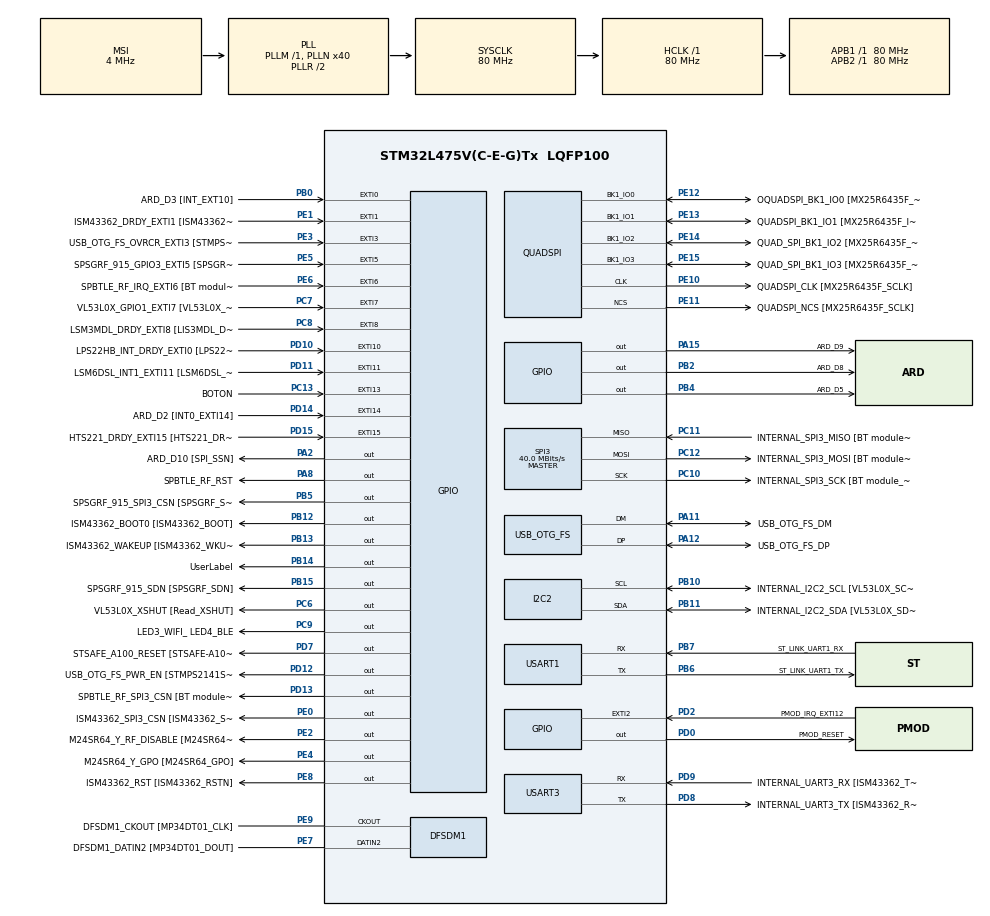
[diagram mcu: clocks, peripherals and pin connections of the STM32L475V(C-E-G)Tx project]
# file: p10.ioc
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FREERTOS.Queues01=qMqttTx,8,1060,1,Dynamic,NULL,NULL;qCmdRx,5,uint8_t,0,Dynamic,NULL,NULL
FREERTOS.Tasks01=WifiTask,24,512,StartWifiTask,Default,NULL,Dynamic,NULL,NULL;MQTT_Task,8,1280,MQTT_TaskFun,Default,NULL,Dynamic,NULL,NULL;task_envRead,24,512,task_envReadFunc,Default,NULL,Dynamic,NULL,NULL;Accel_Task,24,1024,Accel_Task_Func,Default,NULL,Dynamic,NULL,NULL;UartCfgTask,8,512,UartCfgTask_Func,Default,NULL,Dynamic,NULL,NULL
FREERTOS.configTOTAL_HEAP_SIZE=28000
FREERTOS.configUSE_NEWLIB_REENTRANT=1
I2C2.Timing=0x10D19CE4
Mcu.Family=STM32L4
Mcu.Name=STM32L475V(C-E-G)Tx
Mcu.Package=LQFP100
NVIC.EXTI15_10_IRQn=true\:5\:0\:false\:false\:true\:true\:true\:true\:true
NVIC.EXTI1_IRQn=true\:5\:0\:true\:false\:true\:false\:true\:true\:true
NVIC.EXTI9_5_IRQn=true\:5\:0\:false\:false\:true\:true\:true\:true\:true
NVIC.PriorityGroup=NVIC_PRIORITYGROUP_4
NVIC.RTC_Alarm_IRQn=true\:5\:0\:false\:false\:true\:true\:true\:true\:true
NVIC.SPI3_IRQn=true\:5\:0\:true\:false\:false\:false\:true\:true\:true
NVIC.TIM6_DAC_IRQn=true\:15\:0\:false\:false\:true\:false\:false\:true\:true
NVIC.TimeBase=TIM6_DAC_IRQn
NVIC.TimeBaseIP=TIM6
NVIC.USART3_IRQn=true\:5\:0\:false\:false\:true\:true\:true\:true\:true
PA0.GPIO_Label=ARD_D1 [UART4_TX]
PA0.Signal=UART4_TX
PA1.GPIO_Label=ARD_D0 [UART4_RX]
PA1.Signal=UART4_RX
PA10.GPIO_Label=USB_OTG_FS_ID
PA10.Signal=USB_OTG_FS_ID
PA11.GPIO_Label=USB_OTG_FS_DM
PA11.Mode=Device_Only
PA11.Signal=USB_OTG_FS_DM
PA12.GPIO_Label=USB_OTG_FS_DP
PA12.Mode=Device_Only
PA12.Signal=USB_OTG_FS_DP
PA13\ (JTMS-SWDIO).GPIO_Label=SYS_JTMS_SWDIO
PA13\ (JTMS-SWDIO).Mode=Trace_Asynchronous_SW
PA13\ (JTMS-SWDIO).Signal=SYS_JTMS-SWDIO
PA14\ (JTCK-SWCLK).GPIO_Label=SYS_JTCK_SWCLK
PA14\ (JTCK-SWCLK).Mode=Trace_Asynchronous_SW
PA14\ (JTCK-SWCLK).Signal=SYS_JTCK-SWCLK
PA15\ (JTDI).GPIO_Label=ARD_D9
PA15\ (JTDI).Signal=GPIO_Output
PA2.GPIO_Label=ARD_D10 [SPI_SSN]
PA2.Signal=GPIO_Output
PA3.GPIO_Label=ARD_D4
PA3.Signal=S_TIM2_CH4
PA4.GPIO_Label=ARD_D7
PA4.Signal=ADCx_IN9
PA5.GPIO_Label=ARD_D13 [SPI1_SCK]
PA5.Signal=SPI1_SCK
PA6.GPIO_Label=ARD_D12 [SPI1_MISO]
PA6.Signal=SPI1_MISO
PA7.GPIO_Label=ARD_D11 [SPI1_MOSI]
PA7.Signal=SPI1_MOSI
PA8.GPIO_Label=SPBTLE_RF_RST
PA8.Signal=GPIO_Output
PA9.GPIO_Label=USB_OTG_FS_VBUS [STMPS2141STR_OUT]
PA9.Signal=USB_OTG_FS_VBUS
PB0.GPIO_Label=ARD_D3 [INT_EXT10]
PB0.Signal=GPXTI0
PB1.GPIO_Label=ARD_D6 [ADC1_IN6]
PB1.Signal=ADCx_IN16
PB10.GPIO_Label=INTERNAL_I2C2_SCL [VL53L0X_SCL]
PB10.GPIO_Pu=GPIO_PULLUP
PB10.Mode=I2C
PB10.Signal=I2C2_SCL
PB11.GPIO_Label=INTERNAL_I2C2_SDA [VL53L0X_SDA]
PB11.GPIO_Pu=GPIO_PULLUP
PB11.Mode=I2C
PB11.Signal=I2C2_SDA
PB12.GPIO_Label=ISM43362_BOOT0 [ISM43362_BOOT]
PB12.Signal=GPIO_Output
PB13.GPIO_Label=ISM43362_WAKEUP [ISM43362_WKUP]
PB13.Signal=GPIO_Output
PB14.GPIO_Label=UserLabel
PB14.Signal=GPIO_Output
PB15.GPIO_Label=SPSGRF_915_SDN [SPSGRF_SDN]
PB15.Signal=GPIO_Output
PB2.GPIO_Label=ARD_D8
PB2.Signal=GPIO_Output
PB3\ (JTDO-TRACESWO).GPIO_Label=SYS_JTD0_SWO
PB3\ (JTDO-TRACESWO).Mode=Trace_Asynchronous_SW
PB3\ (JTDO-TRACESWO).Signal=SYS_JTDO-SWO
PB4\ (NJTRST).GPIO_Label=ARD_D5
PB4\ (NJTRST).Signal=GPIO_Output
PB5.GPIO_Label=SPSGRF_915_SPI3_CSN [SPSGRF_SPI_CS]
PB5.PinState=GPIO_PIN_SET
PB5.Signal=GPIO_Output
PB6.GPIO_Label=ST_LINK_UART1_TX
PB6.Mode=Asynchronous
PB6.Signal=USART1_TX
PB7.GPIO_Label=ST_LINK_UART1_RX
PB7.Mode=Asynchronous
PB7.Signal=USART1_RX
PB8.GPIO_Label=ARD_D15 [I2C1_SCL]
PB8.Signal=I2C1_SCL
PB9.GPIO_Label=ARD_D14 [I2C1_SDA]
PB9.Signal=I2C1_SDA
PC0.GPIO_Label=ARD_A5 [ADC]
PC0.Signal=ADCx_IN1
PC1.GPIO_Label=ARD_A4 [ADC]
PC1.Signal=ADCx_IN2
PC10.GPIO_Label=INTERNAL_SPI3_SCK [BT module_SPI_SCLK] [ISM43362_SCK]
PC10.Mode=Full_Duplex_Master
PC10.Signal=SPI3_SCK
PC11.GPIO_Label=INTERNAL_SPI3_MISO [BT module_SPI_MISO] [ISM43362_MISO]
PC11.Mode=Full_Duplex_Master
PC11.Signal=SPI3_MISO
PC12.GPIO_Label=INTERNAL_SPI3_MOSI [BT module_SPI_MOSI] [ISM43362_MOSI]
PC12.Mode=Full_Duplex_Master
PC12.Signal=SPI3_MOSI
PC13.GPIO_Label=BOTON
PC13.GPIO_ModeDefaultEXTI=GPIO_MODE_IT_FALLING
PC13.Signal=GPXTI13
PC14-OSC32_IN\ (PC14).Mode=LSE-External-Oscillator
PC14-OSC32_IN\ (PC14).Signal=RCC_OSC32_IN
PC15-OSC32_OUT\ (PC15).Mode=LSE-External-Oscillator
PC15-OSC32_OUT\ (PC15).Signal=RCC_OSC32_OUT
PC2.GPIO_Label=ARD_A3 [ADC]
PC2.Signal=ADCx_IN3
PC3.GPIO_Label=ARD_A2 [ADC]
PC3.Signal=ADCx_IN4
PC4.GPIO_Label=ARD_A1 [ADC]
PC4.Signal=ADCx_IN13
PC5.GPIO_Label=ARD_A0 [ADC]
PC5.Signal=ADCx_IN14
PC6.GPIO_Label=VL53L0X_XSHUT [Read_XSHUT]
PC6.Signal=GPIO_Output
PC7.GPIO_Label=VL53L0X_GPIO1_EXTI7 [VL53L0X_GPIO1]
PC7.Signal=GPXTI7
PC8.GPIO_Label=LSM3MDL_DRDY_EXTI8 [LIS3MDL_DRDY]
PC8.Signal=GPXTI8
PC9.GPIO_Label=LED3_WIFI_ LED4_BLE
PC9.Signal=GPIO_Output
PD0.GPIO_Label=PMOD_RESET
PD0.Signal=GPIO_Output
PD1.GPIO_Label=PMOD_SPI2_SCK
PD1.Signal=SPI2_SCK
PD10.GPIO_Label=LPS22HB_INT_DRDY_EXTI0 [LPS22HB_INT_DRDY] 
PD10.Signal=GPXTI10
PD11.GPIO_Label=LSM6DSL_INT1_EXTI11 [LSM6DSL_INT1]
PD11.Signal=GPXTI11
PD12.GPIO_Label=USB_OTG_FS_PWR_EN [STMPS2141STR_EN]
PD12.Signal=GPIO_Output
PD13.GPIO_Label=SPBTLE_RF_SPI3_CSN [BT module_SPI_CS]
PD13.PinState=GPIO_PIN_SET
PD13.Signal=GPIO_Output
PD14.GPIO_Label=ARD_D2 [INT0_EXTI14]
PD14.Signal=GPXTI14
PD15.GPIO_Label=HTS221_DRDY_EXTI15 [HTS221_DRDY]
PD15.Signal=GPXTI15
PD2.GPIO_Label=PMOD_IRQ_EXTI12
PD2.Signal=GPXTI2
PD3.GPIO_Label=PMOD_UART2_CTS
PD3.Signal=USART2_CTS
PD4.GPIO_Label=PMOD_UART2_RTS
PD4.Signal=USART2_RTS
PD5.GPIO_Label=PMOD_UART2_TX
PD5.Signal=USART2_TX
PD6.GPIO_Label=PMOD_UART2_RX
PD6.Signal=USART2_RX
PD7.GPIO_Label=STSAFE_A100_RESET [STSAFE-A100_RESET]
PD7.Signal=GPIO_Output
PD8.GPIO_Label=INTERNAL_UART3_TX [ISM43362_RX]
PD8.Mode=Asynchronous
PD8.Signal=USART3_TX
PD9.GPIO_Label=INTERNAL_UART3_RX [ISM43362_TX]
PD9.Mode=Asynchronous
PD9.Signal=USART3_RX
PE0.GPIO_Label=ISM43362_SPI3_CSN [ISM43362_SSN]
PE0.PinState=GPIO_PIN_SET
PE0.Signal=GPIO_Output
PE1.GPIO_Label=ISM43362_DRDY_EXTI1 [ISM43362_DATARDY]
PE1.Signal=GPXTI1
PE10.GPIO_Label=QUADSPI_CLK [MX25R6435F_SCLK]
PE10.Mode=Single Bank
PE10.Signal=QUADSPI_CLK
PE11.GPIO_Label=QUADSPI_NCS [MX25R6435F_SCLK]
PE11.Mode=Single Bank
PE11.Signal=QUADSPI_NCS
PE12.GPIO_Label=OQUADSPI_BK1_IO0 [MX25R6435F_IO0]
PE12.Mode=Single Bank
PE12.Signal=QUADSPI_BK1_IO0
PE13.GPIO_Label=QUADSPI_BK1_IO1 [MX25R6435F_IO1]
PE13.Mode=Single Bank
PE13.Signal=QUADSPI_BK1_IO1
PE14.GPIO_Label=QUAD_SPI_BK1_IO2 [MX25R6435F_IO2]
PE14.Mode=Single Bank
PE14.Signal=QUADSPI_BK1_IO2
PE15.GPIO_Label=QUAD_SPI_BK1_IO3 [MX25R6435F_IO3]
PE15.Mode=Single Bank
PE15.Signal=QUADSPI_BK1_IO3
PE2.GPIO_Label=M24SR64_Y_RF_DISABLE [M24SR64_RFDIS]
PE2.Signal=GPIO_Output
PE3.GPIO_Label=USB_OTG_FS_OVRCR_EXTI3 [STMPS2141STR_FAULT]
PE3.Signal=GPXTI3
PE4.GPIO_Label=M24SR64_Y_GPO [M24SR64_GPO]
PE4.Signal=GPIO_Output
PE5.GPIO_Label=SPSGRF_915_GPIO3_EXTI5 [SPSGRF_GPIO_3]
PE5.Signal=GPXTI5
PE6.GPIO_Label=SPBTLE_RF_IRQ_EXTI6 [BT module_SPI_IRQ]
PE6.Signal=GPXTI6
PE7.GPIO_Label=DFSDM1_DATIN2 [MP34DT01_DOUT]
PE7.Signal=S_DATAIN2DFSDM1
PE8.GPIO_Label=ISM43362_RST [ISM43362_RSTN]
PE8.Signal=GPIO_Output
PE9.GPIO_Label=DFSDM1_CKOUT [MP34DT01_CLK]
PE9.Signal=S_CKOUTDFSDM1
ProjectManager.HeapSize=0x200
ProjectManager.StackSize=0x400
ProjectManager.TargetToolchain=STM32CubeIDE
QUADSPI.ClockPrescaler=2
QUADSPI.FifoThreshold=4
QUADSPI.FlashSize=23
QUADSPI.SampleShifting=QSPI_SAMPLE_SHIFTING_HALFCYCLE
RCC.ADCFreq_Value=48000000
RCC.AHBFreq_Value=80000000
RCC.APB1Freq_Value=80000000
RCC.APB1TimFreq_Value=80000000
RCC.APB2Freq_Value=80000000
RCC.APB2TimFreq_Value=80000000
RCC.CortexFreq_Value=80000000
RCC.HCLKFreq_Value=80000000
RCC.HSE_VALUE=8000000
RCC.HSI_VALUE=16000000
RCC.MSI_VALUE=4000000
RCC.PLLN=40
RCC.PLLSAI1N=24
RCC.SYSCLKFreq_VALUE=80000000
RCC.SYSCLKSource=RCC_SYSCLKSOURCE_PLLCLK
RCC.USBFreq_Value=48000000
RCC.VCOOutputFreq_Value=160000000
RTC.Alarm-Alarm\ A=RTC_ALARM_A
SH.ADCx_IN1.0=ADC1_IN1
SH.ADCx_IN13.0=ADC1_IN13
SH.ADCx_IN14.0=ADC1_IN14
SH.ADCx_IN16.0=ADC1_IN16
SH.ADCx_IN2.0=ADC1_IN2
SH.ADCx_IN3.0=ADC1_IN3
SH.ADCx_IN4.0=ADC1_IN4
SH.ADCx_IN9.0=ADC1_IN9
SH.S_CKOUTDFSDM1.0=DFSDM1_CKOUT,CKOUT
SH.S_CKOUTDFSDM1.1=DFSDM1_CKOUT,PDM_SPI_Input_from_ch12_and_Internal_Clock
SH.S_DATAIN2DFSDM1.0=DFSDM1_DATIN2,PDM_SPI_Input_from_ch12_and_Internal_Clock
SH.S_TIM2_CH4.0=TIM2_CH4
SPI3.CalculateBaudRate=40.0 MBits/s
SPI3.Direction=SPI_DIRECTION_2LINES
SPI3.Mode=SPI_MODE_MASTER
SPI3.VirtualType=VM_MASTER
USART1.VirtualMode-Asynchronous=VM_ASYNC
USART3.VirtualMode-Asynchronous=VM_ASYNC
USB_OTG_FS.VirtualMode=Device_Only
VP_FREERTOS_VS_CMSIS_V2.Mode=CMSIS_V2
VP_RTC_VS_RTC_Activate.Mode=RTC_Enabled
VP_RTC_VS_RTC_Alarm_A_Intern.Mode=Alarm A
VP_RTC_VS_RTC_Calendar.Mode=RTC_Calendar
VP_SYS_VS_tim6.Mode=TIM6
board=B-L475E-IOT01A1

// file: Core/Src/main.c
/* USER CODE BEGIN Header */
/**
  ******************************************************************************
  * @file           : main.c
  * @brief          : Main program body
  ******************************************************************************
  * @attention
  *
  * Copyright (c) 2026 STMicroelectronics.
  * All rights reserved.
  *
  * This software is licensed under terms that can be found in the LICENSE file
  * in the root directory of this software component.
  * If no LICENSE file comes with this software, it is provided AS-IS.
  *
  ******************************************************************************
  */
/* USER CODE END Header */
#include "main.h"
#include "cmsis_os.h"

/* USER CODE BEGIN Includes */
#include "common_def.h"
#include "cmd_parser.h"
#include "es_wifi.h"
#include "wifi.h"
#include "stm32l4xx_hal_uart.h"
#include "stdio.h"
#include "mqtt_priv.h"
#include "mqtt_priv_config.h"
//#include "transport_interface.h"
#include "stm32l475e_iot01.h"
#include "stm32l475e_iot01_tsensor.h"
#include "stm32l475e_iot01_hsensor.h"
#include "lsm6dsl.h"
#include"stm32l475e_iot01_accelero.h"
#include <string.h>
#include <stdarg.h>

/* USER CODE END Includes */

/* USER CODE BEGIN PD */
#define FLAG_DATA_READY 0x00000001U
/* ===== DEBUG MENU ===== */
#ifdef DEBUG
  #define DEBUG_MENU 1
#else
  #define DEBUG_MENU 0
#endif

/*
 * Vasriable para el tipo de nodo
 * 1 == ACELEROMETRO
 * 2 == ENVIRONMENT
 * */
#define NODE_ID 1

//#define PROJECT_TYPE 0
/* USER CODE END PD */

DFSDM_Channel_HandleTypeDef hdfsdm1_channel1;

I2C_HandleTypeDef hi2c2;

QSPI_HandleTypeDef hqspi;

RTC_HandleTypeDef hrtc;

SPI_HandleTypeDef hspi3;

UART_HandleTypeDef huart1;
UART_HandleTypeDef huart3;

PCD_HandleTypeDef hpcd_USB_OTG_FS;

/* Definitions for WifiTask */
osThreadId_t WifiTaskHandle;
const osThreadAttr_t WifiTask_attributes = {
  .name = "WifiTask",
  .stack_size = 512 * 4,
  .priority = (osPriority_t) osPriorityNormal,
};
/* Definitions for MQTT_Task */
osThreadId_t MQTT_TaskHandle;
const osThreadAttr_t MQTT_Task_attributes = {
  .name = "MQTT_Task",
  .stack_size = 1024 * 4,
  .priority = (osPriority_t) osPriorityLow,
};
/* Definitions for task_envRead */
osThreadId_t task_envReadHandle;
const osThreadAttr_t task_envRead_attributes = {
  .name = "task_envRead",
  .stack_size = 512 * 4,
  .priority = (osPriority_t) osPriorityNormal,
};
/* Definitions for Accel_Task */
osThreadId_t Accel_TaskHandle;
const osThreadAttr_t Accel_Task_attributes = {
  .name = "Accel_Task",
  .stack_size = 1024 * 4,
  .priority = (osPriority_t) osPriorityNormal,
};
/* Definitions for UartCfgTask */
osThreadId_t UartCfgTaskHandle;
const osThreadAttr_t UartCfgTask_attributes = {
  .name = "UartCfgTask",
  .stack_size = 512 * 4,
  .priority = (osPriority_t) osPriorityLow,
};
/* Definitions for qMqttTx */
osMessageQueueId_t qMqttTxHandle;
const osMessageQueueAttr_t qMqttTx_attributes = {
  .name = "qMqttTx"
};
/* Definitions for qCmdRx */
osMessageQueueId_t qCmdRxHandle;
const osMessageQueueAttr_t qCmdRx_attributes = {
  .name = "qCmdRx"
};
/* USER CODE BEGIN PV */

char g_wifi_ssid[WIFI_SSID_MAX] = "manolo";
char g_wifi_pass[WIFI_PASS_MAX] = "123456789";
#define WIFISECURITY WIFI_ECN_WPA2_PSK

volatile uint16_t g_acc_odr_hz = 52;
volatile uint8_t  g_acc_fs_g   = 2;

extern UART_HandleTypeDef huart1;
static osMutexId_t uartTxMutexHandle;
static const osMutexAttr_t uartTxMutex_attributes = { .name = "uartTxMutex" };

static uint8_t  uart_rx_ch;
static char     uart_line[UART_LINE_MAX];
static volatile uint16_t uart_line_len = 0;
static char uart_line_ready[UART_LINE_MAX];
static volatile uint8_t uart_line_has_ready = 0;

// Variables globales de estado
volatile uint8_t WIFI_IS_CONNECTED = 0;
volatile uint8_t NET_MQTT_OK = 0;

volatile uint8_t WIFI_STATE = 0;
// 0=DISCONNECTED, 1=CONNECTING, 2=CONNECTED

#define PORT 	80
#define WIFI_WRITE_TIMEOUT 10000
#define WIFI_READ_TIMEOUT 10000

uint8_t Alert_Flag = 0;

/*#define TERMINAL_USE
#ifdef  TERMINAL_USE
#else
#define LOG(a)
#endif*/
/* USER CODE END PV */

void SystemClock_Config(void);
static void MX_GPIO_Init(void);
static void MX_DFSDM1_Init(void);
static void MX_I2C2_Init(void);
static void MX_QUADSPI_Init(void);
static void MX_SPI3_Init(void);
static void MX_USART1_UART_Init(void);
static void MX_USART3_UART_Init(void);
static void MX_USB_OTG_FS_PCD_Init(void);
static void MX_RTC_Init(void);
void StartWifiTask(void *argument);
void MQTT_TaskFun(void *argument);
void task_envReadFunc(void *argument);
void Accel_Task_Func(void *argument);
void UartCfgTask_Func(void *argument);
static void ApplyRTC(const typeof(((SystemCommandMsg_t*)0)->u.rtc) *rtc);
static void send_mqtt_msg(const char *topic, const char *payload);

/* USER CODE BEGIN PFP */
extern  SPI_HandleTypeDef hspi;
static  uint8_t  IP_Addr[4];
#if defined (TERMINAL_USE)
extern UART_HandleTypeDef hDiscoUart;
#endif /* TERMINAL_USE */

extern ES_WIFIObject_t    EsWifiObj;

/* USER CODE END PFP */

/* USER CODE BEGIN 0 */

static osMutexId_t printMutexHandle;
static const osMutexAttr_t printMutex_attributes = { .name = "printMutex" };

static void dbg_printf(const char *fmt, ...)
{
  if (__get_IPSR() != 0) return;

  if (printMutexHandle) osMutexAcquire(printMutexHandle, osWaitForever);

  va_list ap;
  va_start(ap, fmt);
  vprintf(fmt, ap);
  va_end(ap);

  if (printMutexHandle) osMutexRelease(printMutexHandle);
}

static void log_printf(const char *fmt, ...)
{
  char line[256];
  va_list ap;
  va_start(ap, fmt);
  vsnprintf(line, sizeof(line), fmt, ap);
  va_end(ap);

  dbg_printf("%s", line);

  if (!NET_MQTT_OK || !WIFI_IS_CONNECTED) return;
  if (strstr(line, "bridge/log/") != NULL) return;
  if (strstr(line, "[MQTT] Enviando Topic: bridge/log/") != NULL) return;

  char topic[MSG_TOPIC_SIZE];
  snprintf(topic, sizeof(topic), "bridge/log/%d", NODE_ID);
  send_mqtt_msg(topic, line);
}

static void PrintDebugMenu(void)
{
#if DEBUG_MENU
  dbg_printf("\r\n");
  dbg_printf("========================================\r\n");
  dbg_printf("   MENU DEBUG - COMANDOS DISPONIBLES\r\n");
  dbg_printf("========================================\r\n");
  dbg_printf("UART (terminal) y MQTT (bridge/cmd/<id>)\r\n");
  dbg_printf("\r\n");
  dbg_printf("Acelerometro:\r\n");
  dbg_printf("  CONT ON              -> modo continuo\r\n");
  dbg_printf("  CONT OFF             -> modo normal\r\n");
  dbg_printf("  READ                 -> forzar lectura\r\n");
  dbg_printf("\r\n");
  dbg_printf("WiFi:\r\n");
  dbg_printf("  WIFI <ssid> <pass>   -> cambiar credenciales\r\n");
  dbg_printf("     ej: WIFI MiRed 12345678\r\n");
  dbg_printf("\r\n");
  dbg_printf("RTC:\r\n");
  dbg_printf("  RTC 2026-02-08 19:30:00\r\n");
  dbg_printf("  RTC 2026 2 8 19 30 0\r\n");
  dbg_printf("\r\n");
  dbg_printf("MQTT topic de control:\r\n");
  dbg_printf("  bridge/cmd/1  (nodo 1)\r\n");
  dbg_printf("  bridge/cmd/2  (nodo 2)\r\n");
  dbg_printf("========================================\r\n\r\n");
#endif
}

static void DispatchCommand(const SystemCommandMsg_t *cmd);

void OnMqttControlMessage(const char *topic, const char *payload)
{
  (void)topic;
  SystemCommandMsg_t cmd;
  if (!Cmd_ParseLine(payload, CMD_SRC_MQTT, &cmd)) {
    dbg_printf("[MQTT][CTRL] cmd invalido: %s\r\n", payload);
    return;
  }
  DispatchCommand(&cmd);
}

static void DispatchCommand(const SystemCommandMsg_t *cmd)
{
  osMessageQueuePut(qCmdRxHandle, cmd, 0, pdMS_TO_TICKS(50));
  #if NODE_ID == NODE_ID_ACCEL
    osThreadFlagsSet(Accel_TaskHandle, NOTE_CMD_RX);
  #elif NODE_ID == NODE_ID_ENV
    osThreadFlagsSet(task_envReadHandle, NOTE_CMD_RX);
  #endif
}

void program_alarm_RTC(void)
{
  RTC_AlarmTypeDef sAlarm = {0};
  RTC_TimeTypeDef  sTime  = {0};
  RTC_DateTypeDef  sDate  = {0};

  HAL_RTC_GetTime(&hrtc, &sTime, RTC_FORMAT_BIN);
  HAL_RTC_GetDate(&hrtc, &sDate, RTC_FORMAT_BIN);
  HAL_RTC_DeactivateAlarm(&hrtc, RTC_ALARM_A);
  __HAL_RTC_ALARM_CLEAR_FLAG(&hrtc, RTC_FLAG_ALRAF);
  __HAL_RTC_ALARM_EXTI_CLEAR_FLAG();

  uint8_t nextMin = sTime.Minutes + 1;
  uint8_t nextHr  = sTime.Hours;

  if (nextMin >= 60) { nextMin = 0; nextHr = (nextHr + 1) % 24; }

  sAlarm.AlarmTime.Hours   = nextHr;
  sAlarm.AlarmTime.Minutes = nextMin;
  sAlarm.AlarmTime.Seconds = 0;

  sAlarm.AlarmMask = RTC_ALARMMASK_DATEWEEKDAY;
  sAlarm.AlarmSubSecondMask = RTC_ALARMSUBSECONDMASK_ALL;
  sAlarm.AlarmDateWeekDaySel = RTC_ALARMDATEWEEKDAYSEL_DATE;
  sAlarm.AlarmDateWeekDay = 1;
  sAlarm.Alarm = RTC_ALARM_A;

  if (HAL_RTC_SetAlarm_IT(&hrtc, &sAlarm, RTC_FORMAT_BIN) != HAL_OK)
  {
    Error_Handler();
  }
}

static void ApplyRTC(const typeof(((SystemCommandMsg_t*)0)->u.rtc) *rtc)
{
  RTC_TimeTypeDef sTime = {0};
  RTC_DateTypeDef sDate = {0};

  sTime.Hours   = rtc->hour;
  sTime.Minutes = rtc->min;
  sTime.Seconds = rtc->sec;
  sTime.DayLightSaving = RTC_DAYLIGHTSAVING_NONE;
  sTime.StoreOperation = RTC_STOREOPERATION_RESET;

  uint16_t y = rtc->year;
  if (y >= 2000) y -= 2000;

  sDate.Year  = (uint8_t)y;
  sDate.Month = rtc->month;
  sDate.Date  = rtc->day;
  sDate.WeekDay = RTC_WEEKDAY_MONDAY;

  HAL_RTC_DeactivateAlarm(&hrtc, RTC_ALARM_A);

  if (HAL_RTC_SetTime(&hrtc, &sTime, RTC_FORMAT_BIN) != HAL_OK) {
	dbg_printf("[RTC] Error SetTime\r\n");
    return;
  }
  if (HAL_RTC_SetDate(&hrtc, &sDate, RTC_FORMAT_BIN) != HAL_OK) {
	dbg_printf("[RTC] Error SetDate\r\n");
    return;
  }

  dbg_printf("[RTC] Ajustado: %04u-%02u-%02u %02u:%02u:%02u\r\n",
         (unsigned)rtc->year, rtc->month, rtc->day,
         rtc->hour, rtc->min, rtc->sec);
}

static int wifi_start(void)
{
	uint8_t  MAC_Addr[6];
 /*Initialize and use WIFI module */
  if(WIFI_Init() ==  WIFI_STATUS_OK)
  {
    log_printf("ES-WIFI Initialized.\r\n");
    if(WIFI_GetMAC_Address(MAC_Addr) == WIFI_STATUS_OK)
    {
    	dbg_printf("> eS-WiFi module MAC Address : %02X:%02X:%02X:%02X:%02X:%02X\r\n",
               MAC_Addr[0],
               MAC_Addr[1],
               MAC_Addr[2],
               MAC_Addr[3],
               MAC_Addr[4],
               MAC_Addr[5]);
    }
    else
    {
    	log_printf("> ERROR : CANNOT get MAC address\r\n");
      return -1;
    }
  }
  else
  {
    return -1;
  }
  return 0;
}

int wifi_connect(void)
{

  wifi_start();

  log_printf("\nConnecting to %s, %s\r\n", g_wifi_ssid, g_wifi_pass);
  if( WIFI_Connect(g_wifi_ssid, g_wifi_pass, WIFISECURITY) == WIFI_STATUS_OK)
  {
    if(WIFI_GetIP_Address(IP_Addr) == WIFI_STATUS_OK)
    {
    	dbg_printf("> es-wifi module connected: got IP Address : %d.%d.%d.%d\r\n",
               IP_Addr[0],
               IP_Addr[1],
               IP_Addr[2],
               IP_Addr[3]);
    }
    else
    {
    	log_printf(" ERROR : es-wifi module CANNOT get IP address\r\n");
      return -1;
    }
  }
  else
  {
	  dbg_printf("ERROR : es-wifi module NOT connected\r\n");
     return -1;
  }
  return 0;
}

void USART1_IRQHandler(void)
{
  HAL_UART_IRQHandler(&huart1);
}
/* USER CODE END 0 */

int main(void)
{

  /* MCU Configuration--------------------------------------------------------*/

  /* Reset of all peripherals, Initializes the Flash interface and the Systick. */
  HAL_Init();

  /* Configure the system clock */
  SystemClock_Config();

  /* Initialize all configured peripherals */
  MX_GPIO_Init();
  MX_DFSDM1_Init();
  MX_I2C2_Init();
  MX_QUADSPI_Init();
  MX_SPI3_Init();
  MX_USART1_UART_Init();
  MX_USART3_UART_Init();
  MX_USB_OTG_FS_PCD_Init();
  MX_RTC_Init();

  /* USER CODE BEGIN 2 */

	log_printf("[BOOT] Forzando Reinicio Fisico del WiFi ---\r\n");

	HAL_GPIO_WritePin(GPIOE, GPIO_PIN_8, GPIO_PIN_RESET);
	HAL_Delay(500);
	HAL_GPIO_WritePin(GPIOE, GPIO_PIN_8, GPIO_PIN_SET);
	HAL_Delay(1000);

	log_printf("[BOOT] WiFi Reiniciado. Iniciando Kernel... ---\r\n");
    HAL_UART_Receive_IT(&huart1, &uart_rx_ch, 1);
    log_printf("[UART] RX listo\r\n");

	PrintDebugMenu();

  /* USER CODE END 2 */

  /* Init scheduler */
  osKernelInitialize();

  /* USER CODE BEGIN RTOS_MUTEX */
  /* add mutexes, ... */
  uartTxMutexHandle = osMutexNew(&uartTxMutex_attributes);
  printMutexHandle = osMutexNew(&printMutex_attributes);

  /* USER CODE END RTOS_MUTEX */

  /* Create the queue(s) */
  /* creation of qMqttTx */
  qMqttTxHandle = osMessageQueueNew (8, sizeof(MqttMsg_t*), &qMqttTx_attributes);

  /* creation of qCmdRx */
  qCmdRxHandle = osMessageQueueNew (5, sizeof(SystemCommandMsg_t), &qCmdRx_attributes);

  /* Create the thread(s) */
  /* creation of WifiTask */
  WifiTaskHandle = osThreadNew(StartWifiTask, NULL, &WifiTask_attributes);

  /* creation of MQTT_Task */
  MQTT_TaskHandle = osThreadNew(MQTT_TaskFun, NULL, &MQTT_Task_attributes);

#if NODE_ID == 1   // ACC
  Accel_TaskHandle = osThreadNew(Accel_Task_Func, NULL, &Accel_Task_attributes);
#elif NODE_ID == 2 // ENV
  task_envReadHandle = osThreadNew(task_envReadFunc, NULL, &task_envRead_attributes);
#endif

  /* creation of UartCfgTask */
  UartCfgTaskHandle = osThreadNew(UartCfgTask_Func, NULL, &UartCfgTask_attributes);

  /* Start scheduler */
  osKernelStart();

  /* We should never get here as control is now taken by the scheduler */

  /* Infinite loop */
  while (1)
  {

  }
}

void SystemClock_Config(void)
{
  RCC_OscInitTypeDef RCC_OscInitStruct = {0};
  RCC_ClkInitTypeDef RCC_ClkInitStruct = {0};

  /** Configure the main internal regulator output voltage
  */
  if (HAL_PWREx_ControlVoltageScaling(PWR_REGULATOR_VOLTAGE_SCALE1) != HAL_OK)
  {
    Error_Handler();
  }

  /** Configure LSE Drive Capability
  */
  HAL_PWR_EnableBkUpAccess();
  __HAL_RCC_LSEDRIVE_CONFIG(RCC_LSEDRIVE_LOW);

  /** Initializes the RCC Oscillators according to the specified parameters
  * in the RCC_OscInitTypeDef structure.
  */
  RCC_OscInitStruct.OscillatorType = RCC_OSCILLATORTYPE_LSI|RCC_OSCILLATORTYPE_LSE
                              |RCC_OSCILLATORTYPE_MSI;
  RCC_OscInitStruct.LSEState = RCC_LSE_ON;
  RCC_OscInitStruct.LSIState = RCC_LSI_ON;
  RCC_OscInitStruct.MSIState = RCC_MSI_ON;
  RCC_OscInitStruct.MSICalibrationValue = 0;
  RCC_OscInitStruct.MSIClockRange = RCC_MSIRANGE_6;
  RCC_OscInitStruct.PLL.PLLState = RCC_PLL_ON;
  RCC_OscInitStruct.PLL.PLLSource = RCC_PLLSOURCE_MSI;
  RCC_OscInitStruct.PLL.PLLM = 1;
  RCC_OscInitStruct.PLL.PLLN = 40;
  RCC_OscInitStruct.PLL.PLLP = RCC_PLLP_DIV7;
  RCC_OscInitStruct.PLL.PLLQ = RCC_PLLQ_DIV2;
  RCC_OscInitStruct.PLL.PLLR = RCC_PLLR_DIV2;
  if (HAL_RCC_OscConfig(&RCC_OscInitStruct) != HAL_OK)
  {
    Error_Handler();
  }

  /** Initializes the CPU, AHB and APB buses clocks
  */
  RCC_ClkInitStruct.ClockType = RCC_CLOCKTYPE_HCLK|RCC_CLOCKTYPE_SYSCLK
                              |RCC_CLOCKTYPE_PCLK1|RCC_CLOCKTYPE_PCLK2;
  RCC_ClkInitStruct.SYSCLKSource = RCC_SYSCLKSOURCE_PLLCLK;
  RCC_ClkInitStruct.AHBCLKDivider = RCC_SYSCLK_DIV1;
  RCC_ClkInitStruct.APB1CLKDivider = RCC_HCLK_DIV1;
  RCC_ClkInitStruct.APB2CLKDivider = RCC_HCLK_DIV1;

  if (HAL_RCC_ClockConfig(&RCC_ClkInitStruct, FLASH_LATENCY_4) != HAL_OK)
  {
    Error_Handler();
  }

  /** Enable MSI Auto calibration
  */
  HAL_RCCEx_EnableMSIPLLMode();
}

static void MX_DFSDM1_Init(void)
{

  hdfsdm1_channel1.Instance = DFSDM1_Channel1;
  hdfsdm1_channel1.Init.OutputClock.Activation = ENABLE;
  hdfsdm1_channel1.Init.OutputClock.Selection = DFSDM_CHANNEL_OUTPUT_CLOCK_SYSTEM;
  hdfsdm1_channel1.Init.OutputClock.Divider = 2;
  hdfsdm1_channel1.Init.Input.Multiplexer = DFSDM_CHANNEL_EXTERNAL_INPUTS;
  hdfsdm1_channel1.Init.Input.DataPacking = DFSDM_CHANNEL_STANDARD_MODE;
  hdfsdm1_channel1.Init.Input.Pins = DFSDM_CHANNEL_FOLLOWING_CHANNEL_PINS;
  hdfsdm1_channel1.Init.SerialInterface.Type = DFSDM_CHANNEL_SPI_RISING;
  hdfsdm1_channel1.Init.SerialInterface.SpiClock = DFSDM_CHANNEL_SPI_CLOCK_INTERNAL;
  hdfsdm1_channel1.Init.Awd.FilterOrder = DFSDM_CHANNEL_FASTSINC_ORDER;
  hdfsdm1_channel1.Init.Awd.Oversampling = 1;
  hdfsdm1_channel1.Init.Offset = 0;
  hdfsdm1_channel1.Init.RightBitShift = 0x00;
  if (HAL_DFSDM_ChannelInit(&hdfsdm1_channel1) != HAL_OK)
  {
    Error_Handler();
  }

}

static void MX_I2C2_Init(void)
{

  hi2c2.Instance = I2C2;
  hi2c2.Init.Timing = 0x10D19CE4;
  hi2c2.Init.OwnAddress1 = 0;
  hi2c2.Init.AddressingMode = I2C_ADDRESSINGMODE_7BIT;
  hi2c2.Init.DualAddressMode = I2C_DUALADDRESS_DISABLE;
  hi2c2.Init.OwnAddress2 = 0;
  hi2c2.Init.OwnAddress2Masks = I2C_OA2_NOMASK;
  hi2c2.Init.GeneralCallMode = I2C_GENERALCALL_DISABLE;
  hi2c2.Init.NoStretchMode = I2C_NOSTRETCH_DISABLE;
  if (HAL_I2C_Init(&hi2c2) != HAL_OK)
  {
    Error_Handler();
  }

  /** Configure Analogue filter
  */
  if (HAL_I2CEx_ConfigAnalogFilter(&hi2c2, I2C_ANALOGFILTER_ENABLE) != HAL_OK)
  {
    Error_Handler();
  }

  /** Configure Digital filter
  */
  if (HAL_I2CEx_ConfigDigitalFilter(&hi2c2, 0) != HAL_OK)
  {
    Error_Handler();
  }

}

static void MX_QUADSPI_Init(void)
{

  /* QUADSPI parameter configuration*/
  hqspi.Instance = QUADSPI;
  hqspi.Init.ClockPrescaler = 2;
  hqspi.Init.FifoThreshold = 4;
  hqspi.Init.SampleShifting = QSPI_SAMPLE_SHIFTING_HALFCYCLE;
  hqspi.Init.FlashSize = 23;
  hqspi.Init.ChipSelectHighTime = QSPI_CS_HIGH_TIME_1_CYCLE;
  hqspi.Init.ClockMode = QSPI_CLOCK_MODE_0;
  if (HAL_QSPI_Init(&hqspi) != HAL_OK)
  {
    Error_Handler();
  }

}

static void MX_RTC_Init(void)
{

  RTC_TimeTypeDef sTime = {0};
  RTC_DateTypeDef sDate = {0};
  RTC_AlarmTypeDef sAlarm = {0};

  /** Initialize RTC Only
  */
  hrtc.Instance = RTC;
  hrtc.Init.HourFormat = RTC_HOURFORMAT_24;
  hrtc.Init.AsynchPrediv = 127;
  hrtc.Init.SynchPrediv = 255;
  hrtc.Init.OutPut = RTC_OUTPUT_DISABLE;
  hrtc.Init.OutPutRemap = RTC_OUTPUT_REMAP_NONE;
  hrtc.Init.OutPutPolarity = RTC_OUTPUT_POLARITY_HIGH;
  hrtc.Init.OutPutType = RTC_OUTPUT_TYPE_OPENDRAIN;
  if (HAL_RTC_Init(&hrtc) != HAL_OK)
  {
    Error_Handler();
  }

  /** Initialize RTC and set the Time and Date
  */
  sTime.Hours = 0x0;
  sTime.Minutes = 0x0;
  sTime.Seconds = 0x0;
  sTime.DayLightSaving = RTC_DAYLIGHTSAVING_NONE;
  sTime.StoreOperation = RTC_STOREOPERATION_RESET;
  if (HAL_RTC_SetTime(&hrtc, &sTime, RTC_FORMAT_BCD) != HAL_OK)
  {
    Error_Handler();
  }
  sDate.WeekDay = RTC_WEEKDAY_MONDAY;
  sDate.Month = RTC_MONTH_JANUARY;
  sDate.Date = 0x1;
  sDate.Year = 0x0;

  if (HAL_RTC_SetDate(&hrtc, &sDate, RTC_FORMAT_BCD) != HAL_OK)
  {
    Error_Handler();
  }

  /** Enable the Alarm A
  */
  sAlarm.AlarmTime.Hours = 0x0;
  sAlarm.AlarmTime.Minutes = 0x0;
  sAlarm.AlarmTime.Seconds = 0x0;
  sAlarm.AlarmTime.SubSeconds = 0x0;
  sAlarm.AlarmTime.DayLightSaving = RTC_DAYLIGHTSAVING_NONE;
  sAlarm.AlarmTime.StoreOperation = RTC_STOREOPERATION_RESET;
  sAlarm.AlarmMask = RTC_ALARMMASK_NONE;
  sAlarm.AlarmSubSecondMask = RTC_ALARMSUBSECONDMASK_ALL;
  sAlarm.AlarmDateWeekDaySel = RTC_ALARMDATEWEEKDAYSEL_DATE;
  sAlarm.AlarmDateWeekDay = 0x1;
  sAlarm.Alarm = RTC_ALARM_A;
  if (HAL_RTC_SetAlarm_IT(&hrtc, &sAlarm, RTC_FORMAT_BCD) != HAL_OK)
  {
    Error_Handler();
  }

}

static void MX_SPI3_Init(void)
{

  /* SPI3 parameter configuration*/
  hspi3.Instance = SPI3;
  hspi3.Init.Mode = SPI_MODE_MASTER;
  hspi3.Init.Direction = SPI_DIRECTION_2LINES;
  hspi3.Init.DataSize = SPI_DATASIZE_4BIT;
  hspi3.Init.CLKPolarity = SPI_POLARITY_LOW;
  hspi3.Init.CLKPhase = SPI_PHASE_1EDGE;
  hspi3.Init.NSS = SPI_NSS_SOFT;
  hspi3.Init.BaudRatePrescaler = SPI_BAUDRATEPRESCALER_2;
  hspi3.Init.FirstBit = SPI_FIRSTBIT_MSB;
  hspi3.Init.TIMode = SPI_TIMODE_DISABLE;
  hspi3.Init.CRCCalculation = SPI_CRCCALCULATION_DISABLE;
  hspi3.Init.CRCPolynomial = 7;
  hspi3.Init.CRCLength = SPI_CRC_LENGTH_DATASIZE;
  hspi3.Init.NSSPMode = SPI_NSS_PULSE_ENABLE;
  if (HAL_SPI_Init(&hspi3) != HAL_OK)
  {
    Error_Handler();
  }

}

static void MX_USART1_UART_Init(void)
{

  huart1.Instance = USART1;
  huart1.Init.BaudRate = 115200;
  huart1.Init.WordLength = UART_WORDLENGTH_8B;
  huart1.Init.StopBits = UART_STOPBITS_1;
  huart1.Init.Parity = UART_PARITY_NONE;
  huart1.Init.Mode = UART_MODE_TX_RX;
  huart1.Init.HwFlowCtl = UART_HWCONTROL_NONE;
  huart1.Init.OverSampling = UART_OVERSAMPLING_16;
  huart1.Init.OneBitSampling = UART_ONE_BIT_SAMPLE_DISABLE;
  huart1.AdvancedInit.AdvFeatureInit = UART_ADVFEATURE_NO_INIT;
  if (HAL_UART_Init(&huart1) != HAL_OK)
  {
    Error_Handler();
  }
  /* USER CODE BEGIN USART1_Init 2 */

  HAL_NVIC_SetPriority(USART1_IRQn, 5, 0);
  HAL_NVIC_EnableIRQ(USART1_IRQn);

  /* USER CODE END USART1_Init 2 */

}

static void MX_USART3_UART_Init(void)
{

  huart3.Instance = USART3;
  huart3.Init.BaudRate = 115200;
  huart3.Init.WordLength = UART_WORDLENGTH_8B;
  huart3.Init.StopBits = UART_STOPBITS_1;
  huart3.Init.Parity = UART_PARITY_NONE;
  huart3.Init.Mode = UART_MODE_TX_RX;
  huart3.Init.HwFlowCtl = UART_HWCONTROL_NONE;
  huart3.Init.OverSampling = UART_OVERSAMPLING_16;
  huart3.Init.OneBitSampling = UART_ONE_BIT_SAMPLE_DISABLE;
  huart3.AdvancedInit.AdvFeatureInit = UART_ADVFEATURE_NO_INIT;
  if (HAL_UART_Init(&huart3) != HAL_OK)
  {
    Error_Handler();
  }

}

static void MX_USB_OTG_FS_PCD_Init(void)
{

  hpcd_USB_OTG_FS.Instance = USB_OTG_FS;
  hpcd_USB_OTG_FS.Init.dev_endpoints = 6;
  hpcd_USB_OTG_FS.Init.speed = PCD_SPEED_FULL;
  hpcd_USB_OTG_FS.Init.phy_itface = PCD_PHY_EMBEDDED;
  hpcd_USB_OTG_FS.Init.Sof_enable = DISABLE;
  hpcd_USB_OTG_FS.Init.low_power_enable = DISABLE;
  hpcd_USB_OTG_FS.Init.lpm_enable = DISABLE;
  hpcd_USB_OTG_FS.Init.battery_charging_enable = DISABLE;
  hpcd_USB_OTG_FS.Init.use_dedicated_ep1 = DISABLE;
  hpcd_USB_OTG_FS.Init.vbus_sensing_enable = DISABLE;
  if (HAL_PCD_Init(&hpcd_USB_OTG_FS) != HAL_OK)
  {
    Error_Handler();
  }

}

static void MX_GPIO_Init(void)
{
  GPIO_InitTypeDef GPIO_InitStruct = {0};

  /* GPIO Ports Clock Enable */
  __HAL_RCC_GPIOE_CLK_ENABLE();
  __HAL_RCC_GPIOC_CLK_ENABLE();
  __HAL_RCC_GPIOA_CLK_ENABLE();
  __HAL_RCC_GPIOB_CLK_ENABLE();
  __HAL_RCC_GPIOD_CLK_ENABLE();

  /*Configure GPIO pin Output Level */
  HAL_GPIO_WritePin(GPIOE, M24SR64_Y_RF_DISABLE_Pin|M24SR64_Y_GPO_Pin|ISM43362_RST_Pin, GPIO_PIN_RESET);

  /*Configure GPIO pin Output Level */
  HAL_GPIO_WritePin(GPIOA, ARD_D10_Pin|SPBTLE_RF_RST_Pin|ARD_D9_Pin, GPIO_PIN_RESET);

  /*Configure GPIO pin Output Level */
  HAL_GPIO_WritePin(GPIOB, ARD_D8_Pin|ISM43362_BOOT0_Pin|ISM43362_WAKEUP_Pin|UserLabel_Pin
                          |SPSGRF_915_SDN_Pin|ARD_D5_Pin, GPIO_PIN_RESET);

  /*Configure GPIO pin Output Level */
  HAL_GPIO_WritePin(GPIOD, USB_OTG_FS_PWR_EN_Pin|PMOD_RESET_Pin|STSAFE_A100_RESET_Pin, GPIO_PIN_RESET);

  /*Configure GPIO pin Output Level */
  HAL_GPIO_WritePin(SPBTLE_RF_SPI3_CSN_GPIO_Port, SPBTLE_RF_SPI3_CSN_Pin, GPIO_PIN_SET);

  /*Configure GPIO pin Output Level */
  HAL_GPIO_WritePin(GPIOC, VL53L0X_XSHUT_Pin|LED3_WIFI__LED4_BLE_Pin, GPIO_PIN_RESET);

  /*Configure GPIO pin Output Level */
  HAL_GPIO_WritePin(SPSGRF_915_SPI3_CSN_GPIO_Port, SPSGRF_915_SPI3_CSN_Pin, GPIO_PIN_SET);

  /*Configure GPIO pin Output Level */
  HAL_GPIO_WritePin(ISM43362_SPI3_CSN_GPIO_Port, ISM43362_SPI3_CSN_Pin, GPIO_PIN_SET);

  /*Configure GPIO pins : M24SR64_Y_RF_DISABLE_Pin M24SR64_Y_GPO_Pin ISM43362_RST_Pin ISM43362_SPI3_CSN_Pin */
  GPIO_InitStruct.Pin = M24SR64_Y_RF_DISABLE_Pin|M24SR64_Y_GPO_Pin|ISM43362_RST_Pin|ISM43362_SPI3_CSN_Pin;
  GPIO_InitStruct.Mode = GPIO_MODE_OUTPUT_PP;
  GPIO_InitStruct.Pull = GPIO_NOPULL;
  GPIO_InitStruct.Speed = GPIO_SPEED_FREQ_LOW;
  HAL_GPIO_Init(GPIOE, &GPIO_InitStruct);

  /*Configure GPIO pins : USB_OTG_FS_OVRCR_EXTI3_Pin SPSGRF_915_GPIO3_EXTI5_Pin SPBTLE_RF_IRQ_EXTI6_Pin ISM43362_DRDY_EXTI1_Pin */
  GPIO_InitStruct.Pin = USB_OTG_FS_OVRCR_EXTI3_Pin|SPSGRF_915_GPIO3_EXTI5_Pin|SPBTLE_RF_IRQ_EXTI6_Pin|ISM43362_DRDY_EXTI1_Pin;
  GPIO_InitStruct.Mode = GPIO_MODE_IT_RISING;
  GPIO_InitStruct.Pull = GPIO_NOPULL;
  HAL_GPIO_Init(GPIOE, &GPIO_InitStruct);

  /*Configure GPIO pin : BOTON_Pin */
  GPIO_InitStruct.Pin = BOTON_Pin;
  GPIO_InitStruct.Mode = GPIO_MODE_IT_FALLING;
  GPIO_InitStruct.Pull = GPIO_NOPULL;
  HAL_GPIO_Init(BOTON_GPIO_Port, &GPIO_InitStruct);

  /*Configure GPIO pins : ARD_A5_Pin ARD_A4_Pin ARD_A3_Pin ARD_A2_Pin
                           ARD_A1_Pin ARD_A0_Pin */
  GPIO_InitStruct.Pin = ARD_A5_Pin|ARD_A4_Pin|ARD_A3_Pin|ARD_A2_Pin
                          |ARD_A1_Pin|ARD_A0_Pin;
  GPIO_InitStruct.Mode = GPIO_MODE_ANALOG_ADC_CONTROL;
  GPIO_InitStruct.Pull = GPIO_NOPULL;
  HAL_GPIO_Init(GPIOC, &GPIO_InitStruct);

  /*Configure GPIO pins : ARD_D1_Pin ARD_D0_Pin */
  GPIO_InitStruct.Pin = ARD_D1_Pin|ARD_D0_Pin;
  GPIO_InitStruct.Mode = GPIO_MODE_AF_PP;
  GPIO_InitStruct.Pull = GPIO_NOPULL;
  GPIO_InitStruct.Speed = GPIO_SPEED_FREQ_VERY_HIGH;
  GPIO_InitStruct.Alternate = GPIO_AF8_UART4;
  HAL_GPIO_Init(GPIOA, &GPIO_InitStruct);

  /*Configure GPIO pins : ARD_D10_Pin SPBTLE_RF_RST_Pin ARD_D9_Pin */
  GPIO_InitStruct.Pin = ARD_D10_Pin|SPBTLE_RF_RST_Pin|ARD_D9_Pin;
  GPIO_InitStruct.Mode = GPIO_MODE_OUTPUT_PP;
  GPIO_InitStruct.Pull = GPIO_NOPULL;
  GPIO_InitStruct.Speed = GPIO_SPEED_FREQ_LOW;
  HAL_GPIO_Init(GPIOA, &GPIO_InitStruct);

  /*Configure GPIO pin : ARD_D4_Pin */
  GPIO_InitStruct.Pin = ARD_D4_Pin;
  GPIO_InitStruct.Mode = GPIO_MODE_AF_PP;
  GPIO_InitStruct.Pull = GPIO_NOPULL;
  GPIO_InitStruct.Speed = GPIO_SPEED_FREQ_LOW;
  GPIO_InitStruct.Alternate = GPIO_AF1_TIM2;
  HAL_GPIO_Init(ARD_D4_GPIO_Port, &GPIO_InitStruct);

  /*Configure GPIO pin : ARD_D7_Pin */
  GPIO_InitStruct.Pin = ARD_D7_Pin;
  GPIO_InitStruct.Mode = GPIO_MODE_ANALOG_ADC_CONTROL;
  GPIO_InitStruct.Pull = GPIO_NOPULL;
  HAL_GPIO_Init(ARD_D7_GPIO_Port, &GPIO_InitStruct);

  /*Configure GPIO pins : ARD_D13_Pin ARD_D12_Pin ARD_D11_Pin */
  GPIO_InitStruct.Pin = ARD_D13_Pin|ARD_D12_Pin|ARD_D11_Pin;
  GPIO_InitStruct.Mode = GPIO_MODE_AF_PP;
  GPIO_InitStruct.Pull = GPIO_NOPULL;
  GPIO_InitStruct.Speed = GPIO_SPEED_FREQ_VERY_HIGH;
  GPIO_InitStruct.Alternate = GPIO_AF5_SPI1;
  HAL_GPIO_Init(GPIOA, &GPIO_InitStruct);

  /*Configure GPIO pin : ARD_D3_Pin */
  GPIO_InitStruct.Pin = ARD_D3_Pin;
  GPIO_InitStruct.Mode = GPIO_MODE_IT_RISING;
  GPIO_InitStruct.Pull = GPIO_NOPULL;
  HAL_GPIO_Init(ARD_D3_GPIO_Port, &GPIO_InitStruct);

  /*Configure GPIO pin : ARD_D6_Pin */
  GPIO_InitStruct.Pin = ARD_D6_Pin;
  GPIO_InitStruct.Mode = GPIO_MODE_ANALOG_ADC_CONTROL;
  GPIO_InitStruct.Pull = GPIO_NOPULL;
  HAL_GPIO_Init(ARD_D6_GPIO_Port, &GPIO_InitStruct);

  /*Configure GPIO pins : ARD_D8_Pin ISM43362_BOOT0_Pin ISM43362_WAKEUP_Pin UserLabel_Pin
                           SPSGRF_915_SDN_Pin ARD_D5_Pin SPSGRF_915_SPI3_CSN_Pin */
  GPIO_InitStruct.Pin = ARD_D8_Pin|ISM43362_BOOT0_Pin|ISM43362_WAKEUP_Pin|UserLabel_Pin
                          |SPSGRF_915_SDN_Pin|ARD_D5_Pin|SPSGRF_915_SPI3_CSN_Pin;
  GPIO_InitStruct.Mode = GPIO_MODE_OUTPUT_PP;
  GPIO_InitStruct.Pull = GPIO_NOPULL;
  GPIO_InitStruct.Speed = GPIO_SPEED_FREQ_LOW;
  HAL_GPIO_Init(GPIOB, &GPIO_InitStruct);

  /*Configure GPIO pins : LPS22HB_INT_DRDY_EXTI0_Pin LSM6DSL_INT1_EXTI11_Pin ARD_D2_Pin HTS221_DRDY_EXTI15_Pin
                           PMOD_IRQ_EXTI12_Pin */
  GPIO_InitStruct.Pin = LPS22HB_INT_DRDY_EXTI0_Pin|LSM6DSL_INT1_EXTI11_Pin|ARD_D2_Pin|HTS221_DRDY_EXTI15_Pin
                          |PMOD_IRQ_EXTI12_Pin;
  GPIO_InitStruct.Mode = GPIO_MODE_IT_RISING;
  GPIO_InitStruct.Pull = GPIO_NOPULL;
  HAL_GPIO_Init(GPIOD, &GPIO_InitStruct);

  /*Configure GPIO pins : USB_OTG_FS_PWR_EN_Pin SPBTLE_RF_SPI3_CSN_Pin PMOD_RESET_Pin STSAFE_A100_RESET_Pin */
  GPIO_InitStruct.Pin = USB_OTG_FS_PWR_EN_Pin|SPBTLE_RF_SPI3_CSN_Pin|PMOD_RESET_Pin|STSAFE_A100_RESET_Pin;
  GPIO_InitStruct.Mode = GPIO_MODE_OUTPUT_PP;
  GPIO_InitStruct.Pull = GPIO_NOPULL;
  GPIO_InitStruct.Speed = GPIO_SPEED_FREQ_LOW;
  HAL_GPIO_Init(GPIOD, &GPIO_InitStruct);

  /*Configure GPIO pins : VL53L0X_XSHUT_Pin LED3_WIFI__LED4_BLE_Pin */
  GPIO_InitStruct.Pin = VL53L0X_XSHUT_Pin|LED3_WIFI__LED4_BLE_Pin;
  GPIO_InitStruct.Mode = GPIO_MODE_OUTPUT_PP;
  GPIO_InitStruct.Pull = GPIO_NOPULL;
  GPIO_InitStruct.Speed = GPIO_SPEED_FREQ_LOW;
  HAL_GPIO_Init(GPIOC, &GPIO_InitStruct);

  /*Configure GPIO pins : VL53L0X_GPIO1_EXTI7_Pin LSM3MDL_DRDY_EXTI8_Pin */
  GPIO_InitStruct.Pin = VL53L0X_GPIO1_EXTI7_Pin|LSM3MDL_DRDY_EXTI8_Pin;
  GPIO_InitStruct.Mode = GPIO_MODE_IT_RISING;
  GPIO_InitStruct.Pull = GPIO_NOPULL;
  HAL_GPIO_Init(GPIOC, &GPIO_InitStruct);

  /*Configure GPIO pin : PMOD_SPI2_SCK_Pin */
  GPIO_InitStruct.Pin = PMOD_SPI2_SCK_Pin;
  GPIO_InitStruct.Mode = GPIO_MODE_AF_PP;
  GPIO_InitStruct.Pull = GPIO_NOPULL;
  GPIO_InitStruct.Speed = GPIO_SPEED_FREQ_VERY_HIGH;
  GPIO_InitStruct.Alternate = GPIO_AF5_SPI2;
  HAL_GPIO_Init(PMOD_SPI2_SCK_GPIO_Port, &GPIO_InitStruct);

  /*Configure GPIO pins : PMOD_UART2_CTS_Pin PMOD_UART2_RTS_Pin PMOD_UART2_TX_Pin PMOD_UART2_RX_Pin */
  GPIO_InitStruct.Pin = PMOD_UART2_CTS_Pin|PMOD_UART2_RTS_Pin|PMOD_UART2_TX_Pin|PMOD_UART2_RX_Pin;
  GPIO_InitStruct.Mode = GPIO_MODE_AF_PP;
  GPIO_InitStruct.Pull = GPIO_NOPULL;
  GPIO_InitStruct.Speed = GPIO_SPEED_FREQ_VERY_HIGH;
  GPIO_InitStruct.Alternate = GPIO_AF7_USART2;
  HAL_GPIO_Init(GPIOD, &GPIO_InitStruct);

  /*Configure GPIO pins : ARD_D15_Pin ARD_D14_Pin */
  GPIO_InitStruct.Pin = ARD_D15_Pin|ARD_D14_Pin;
  GPIO_InitStruct.Mode = GPIO_MODE_AF_OD;
  GPIO_InitStruct.Pull = GPIO_NOPULL;
  GPIO_InitStruct.Speed = GPIO_SPEED_FREQ_VERY_HIGH;
  GPIO_InitStruct.Alternate = GPIO_AF4_I2C1;
  HAL_GPIO_Init(GPIOB, &GPIO_InitStruct);

  /* EXTI interrupt init*/
  HAL_NVIC_SetPriority(EXTI1_IRQn, 5, 0);
  HAL_NVIC_EnableIRQ(EXTI1_IRQn);

  HAL_NVIC_SetPriority(EXTI9_5_IRQn, 5, 0);
  HAL_NVIC_EnableIRQ(EXTI9_5_IRQn);

  HAL_NVIC_SetPriority(EXTI15_10_IRQn, 5, 0);
  HAL_NVIC_EnableIRQ(EXTI15_10_IRQn);

}

/* USER CODE BEGIN 4 */

//int _write(int file, char *ptr, int len)
//{
//	int DataIdx;
//	for(DataIdx=0; DataIdx<len; DataIdx++)
//	{
//		ITM_SendChar(*ptr++);
//	}
//	return len;
//}
//

int _write(int file, char *ptr, int len)
{
  (void)file;

  if (__get_IPSR() == 0) // thread mode
  {
    if (uartTxMutexHandle) osMutexAcquire(uartTxMutexHandle, osWaitForever);

    // 1) SWV
    for (int i = 0; i < len; i++)
      ITM_SendChar(ptr[i]);

    // 2) UART
    HAL_UART_Transmit(&huart1, (uint8_t*)ptr, (uint16_t)len, 1000);

    if (uartTxMutexHandle) osMutexRelease(uartTxMutexHandle);
  }
  else
  {
    // En interrupción: NO UART, y tampoco bloquear con mutex
    for (int i = 0; i < len; i++)
      ITM_SendChar(ptr[i]);
  }

  return len;
}

static void send_mqtt_msg(const char *topic, const char *payload)
{
  // PROTECCIÓN: Solo enviar si MQTT está listo
  if (!NET_MQTT_OK || !WIFI_IS_CONNECTED) {
	return;  // Salir sin intentar malloc
  }
  MqttMsg_t *m = (MqttMsg_t*)pvPortMalloc(sizeof(MqttMsg_t));

  if (m == NULL) {
    dbg_printf("[ERROR] send_mqtt_msg: Sin memoria\r\n");
    return;
  }
  dbg_printf("[MALLOC] msg en heap = %p\r\n", (void*)m);

  memset(m, 0, sizeof(MqttMsg_t));
  strncpy(m->topic, topic, MSG_TOPIC_SIZE - 1);
  m->topic[MSG_TOPIC_SIZE - 1] = '\0';

  strncpy(m->payload, payload, MSG_PAYLOAD_SIZE - 1);
  m->payload[MSG_PAYLOAD_SIZE - 1] = '\0';

  osStatus_t status = osMessageQueuePut(qMqttTxHandle, &m, 0, pdMS_TO_TICKS(100));

  if (status != osOK) {
    dbg_printf("[ERROR] send_mqtt_msg: Cola llena\r\n");
    vPortFree(m);
  }

}

void HAL_UART_RxCpltCallback(UART_HandleTypeDef *huart)
{
  if (huart->Instance == USART1)
  {
    char c = (char)uart_rx_ch;

    if (c == '\r' || c == '\n')
    {
      if (uart_line_len > 0)
      {
    	  uart_line[uart_line_len] = '\0';
    	  strncpy(uart_line_ready, uart_line, UART_LINE_MAX);
    	  uart_line_ready[UART_LINE_MAX-1] = '\0';
    	  uart_line_has_ready = 1;
    	  uart_line_len = 0;
    	  osThreadFlagsSet(UartCfgTaskHandle, NOTE_UART_LINE);

      }
    }
    else
    {
      if (uart_line_len < (UART_LINE_MAX - 1))
        uart_line[uart_line_len++] = c;
      else
        uart_line_len = 0;
    }

    HAL_UART_Receive_IT(&huart1, &uart_rx_ch, 1);
  }
}

void SPI3_IRQHandler(void)
{
  HAL_SPI_IRQHandler(&hspi);
}

void HAL_GPIO_EXTI_Callback(uint16_t GPIO_Pin)
{
  switch (GPIO_Pin)
  {
    case (GPIO_PIN_1):
    {
      SPI_WIFI_ISR();
      break;
    }
    case (BOTON_Pin):
    {
      #if NODE_ID == NODE_ID_ACCEL
      osThreadFlagsSet(Accel_TaskHandle,  NOTE_BUTTON_IRQ);
      #elif NODE_ID == NODE_ID_ENV
      osThreadFlagsSet(task_envReadHandle,  NOTE_BUTTON_IRQ);
      #endif

      break;
    }
    case (LSM6DSL_INT1_EXTI11_Pin):
    {
      #if NODE_ID == NODE_ID_ACCEL
      osThreadFlagsSet(Accel_TaskHandle, NOTE_ACCEL_FIFO);
      #endif
      break;
    }

    default:
    {
      break;
    }
  }
}

/*--------------------------------------------- FUNCIONES TEMP-HUMEDAD --------------------------------------------------------*/

void HAL_RTC_AlarmAEventCallback(RTC_HandleTypeDef *hrtc) {

	#if NODE_ID == NODE_ID_ENV
	  osThreadFlagsSet(task_envReadHandle, FLAG_DATA_READY);

	#elif NODE_ID == NODE_ID_ACCEL
	  osThreadFlagsSet(Accel_TaskHandle, NOTE_RTC_WAKEUP);

	#endif
}

/*--------------------------------------------- FUNCIONES ACCE --------------------------------------------------------*/
#if NODE_ID == NODE_ID_ACCEL

/* Timestamp simple (ms desde arranque) */
static uint32_t now_ms(void)
{
  return (uint32_t)HAL_GetTick();
}

static void build_payload_block(char *dst, size_t dst_sz,
                                uint32_t t0_ms, uint16_t fs_hz,
                                uint16_t seq, uint16_t total,
                                const int16_t *z, uint16_t n)
{
  // JSON compacto y fragmentado:
  // {"t0":123,"fs":52,"s":0,"n":16,"z":[...]}
  size_t off = 0;
  off += (size_t)snprintf(dst + off, dst_sz - off,
                          "{\"t0\":%lu,\"fs\":%u,\"s\":%u,\"n\":%u,\"z\":[",
                          (unsigned long)t0_ms, fs_hz, seq, total);

  for (uint16_t i = 0; i < n && off < dst_sz; i++)
  {
    off += (size_t)snprintf(dst + off, dst_sz - off,
                            (i == 0) ? "%d" : ",%d", (int)z[i]);
  }

  (void)snprintf(dst + off, (off < dst_sz) ? (dst_sz - off) : 0, "]}");
}
#endif

/* USER CODE END 4 */

void StartWifiTask(void *argument)
{

	  int ret;
	  log_printf("--- [WIFI] Tarea iniciada --- \r\n");

	  for(;;)
	  {
	    if (WIFI_STATE == 0) // DISCONNECTED
	    {
	      WIFI_STATE = 1; // CONNECTING
	      dbg_printf("[WIFI] Llamando a wifi_connect()...\r\n");

	      ret = wifi_connect();

	      if (ret == 0)
	      {
	    	log_printf("[WIFI] Conexion Exitosa.\r\n");
	        WIFI_STATE = 2;          // CONNECTED
	        WIFI_IS_CONNECTED = 1;
	      }
	      else
	      {
	    	log_printf("[WIFI] Fallo al conectar. Reintentando en 5s...\r\n");
	        WIFI_STATE = 0;
	        WIFI_IS_CONNECTED = 0;
	        osDelay(pdMS_TO_TICKS(5000));
	      }
	    }
	    else
	    {
	      osDelay(pdMS_TO_TICKS(500));
	    }
	  }
}

void MQTT_TaskFun(void *argument)
{
  /* USER CODE BEGIN MQTT_TaskFun */

	NetworkContext_t xNetworkContext = { 0 };
	MQTTContext_t xMQTTContext;
	TransportStatus_t xTransportStatus;

	osStatus_t qStatus;

	 log_printf("--- [MQTT] Tarea Iniciada ---\r\n");

  /* Infinite loop */
	for(;;)
	  {
		  // 1. ESPERAR A WIFI
		  while (WIFI_IS_CONNECTED == 0) {
			osDelay(pdMS_TO_TICKS(500));
		  }

		  // 2. CONECTAR AL BROKER
		  dbg_printf("[MQTT] Conectando al Broker...\r\n");

		  // Llamada original. Devuelve TransportStatus_t
		  xTransportStatus = prvConnectToServer(&xNetworkContext);

		  if (xTransportStatus != PLAINTEXT_TRANSPORT_SUCCESS) {
			dbg_printf("[MQTT] Error TCP. Reintentando...\r\n");
			osDelay(pdMS_TO_TICKS(2000));
			continue;
		  }

		  // 3. CONECTAR CAPA MQTT
		  prvCreateMQTTConnectionWithBroker(&xMQTTContext, &xNetworkContext);

		  dbg_printf("[MQTT] Loop de transmision activo.\r\n");
		  NET_MQTT_OK = 1;

		  char subTopic[64];
		  snprintf(subTopic, sizeof(subTopic), "%s%d", TOPIC_SUB_CMD_PREFIX, NODE_ID);
		  prvMQTTSubscribeToTopic(&xMQTTContext, subTopic);
		  log_printf("[MQTT] Subscrito a: %s\r\n", subTopic);

		  // 4. BUCLE DE TRANSMISIÓN
		  while (WIFI_IS_CONNECTED == 1)
		  {
		  MqttMsg_t *msg_ptr = NULL;
				qStatus = osMessageQueueGet(qMqttTxHandle, &msg_ptr, NULL, pdMS_TO_TICKS(100));
				if (qStatus == osOK && msg_ptr != NULL)
				{
				  log_printf("[MQTT] Enviando Topic: %s...\r\n", msg_ptr->topic);
				  prvMQTTPublishToTopic(&xMQTTContext, msg_ptr->topic, msg_ptr->payload);

				  vPortFree(msg_ptr);
				  msg_ptr = NULL;
				}

			// KeepAlive
			MQTTStatus_t xStat = MQTT_ProcessLoop(&xMQTTContext);

			if (xStat != MQTTSuccess)
			{
				 dbg_printf("[MQTT] Error KeepAlive. Desconectando...\r\n");
				 break;
			}
		  }

		  // 5. LIMPIEZA
		  NET_MQTT_OK = 0;
		  dbg_printf("[MQTT] Reiniciando ciclo de conexion...\r\n");
		  osDelay(pdMS_TO_TICKS(1000));
	  }
  /* USER CODE END MQTT_TaskFun */
}

#if NODE_ID == NODE_ID_ENV
void task_envReadFunc(void *argument)
{
  /* USER CODE BEGIN task_envReadFunc */

  uint32_t id_msg = 0;    //Id del mensaje
  uint8_t reason;     //Motivo del mensaje
  float temp;         //Temperatura
  int16_t temp_int;  //Temperatura en un entero
  uint8_t hum;         //Humedad
  uint32_t flag;      //Bandera activada
  RTC_TimeTypeDef sTime = {0};
  RTC_DateTypeDef sDate = {0};
  MqttMsg_t msg;      //Mensaje MQTT

  if ( BSP_TSENSOR_Init() == TSENSOR_OK )
  {
	  dbg_printf("[ENV]Sensor de temperatura inicializado correctamente.\r\n");
  }
  else
  {
	  dbg_printf("[ENV]Error en la inicialización del sensor de temperatura.\r\n");
  }

  if ( BSP_HSENSOR_Init() == HSENSOR_OK )
  {
	  dbg_printf("[ENV]Sensor de humedad inicializado correctamente.\r\n");
  }
  else
  {
	  dbg_printf("[ENV]Error en la inicialización del sensor de humedad.\r\n");
  }

  program_alarm_RTC();

  /* Infinite loop */

  for(;;)
  {

	  flag = osThreadFlagsWait(NOTE_BUTTON_IRQ | FLAG_DATA_READY | NOTE_CMD_RX,
	                           osFlagsWaitAny, osWaitForever);

	  if (flag & NOTE_CMD_RX)
	  {
	    SystemCommandMsg_t cmd;
	    while (osMessageQueueGet(qCmdRxHandle, &cmd, NULL, 0) == osOK)
	    {
	      if (cmd.type == CMD_FORCE_READ)
	      {

	        flag |= FLAG_DATA_READY;
	      }
	      else if (cmd.type == CMD_SET_WIFI)
	      {
	        strncpy(g_wifi_ssid, cmd.u.wifi.ssid, WIFI_SSID_MAX);
	        strncpy(g_wifi_pass, cmd.u.wifi.pass, WIFI_PASS_MAX);
	        WIFI_STATE = 0;
	        WIFI_IS_CONNECTED = 0;
	        NET_MQTT_OK = 0;
	        dbg_printf("[ENV] WIFI cambiado, reconectando...\r\n");
	      }
	      else if (cmd.type == CMD_SET_RTC)
	      {
	        ApplyRTC(&cmd.u.rtc);
	        program_alarm_RTC();
	      }
	    }
	  }

	  if (flag & FLAG_DATA_READY)
	  {
	    reason = 0;
	    program_alarm_RTC();
	  }
	  else if (flag & NOTE_BUTTON_IRQ)
	  {
	    reason = 1;
	  }
	  else
	  {
	    reason = 2;
	  }

    temp = BSP_TSENSOR_ReadTemp();
    temp_int = (int16_t) (temp*10);
    hum = (uint8_t) BSP_HSENSOR_ReadHumidity();

    HAL_RTC_GetTime(&hrtc, &sTime, RTC_FORMAT_BIN);
    HAL_RTC_GetDate(&hrtc, &sDate, RTC_FORMAT_BIN);

    if( (temp_int >= 360) && (Alert_Flag == 0) )
    {
    	Alert_Flag = 1;
    	snprintf(msg.topic, sizeof(msg.topic), "%s1", TOPIC_SUB_CMD_PREFIX); // "bridge/cmd/1"
    	snprintf(msg.payload, sizeof(msg.payload), "CONT ON");               // o "CONT OFF"
    	MqttMsg_t *msg_ptr = (MqttMsg_t*)pvPortMalloc(sizeof(MqttMsg_t));
    	if (msg_ptr != NULL) {
    	  memcpy(msg_ptr, &msg, sizeof(MqttMsg_t));
    	  osStatus_t st = osMessageQueuePut(qMqttTxHandle, &msg_ptr, 0, pdMS_TO_TICKS(100));
    	  if (st != osOK) vPortFree(msg_ptr);
    	}
    }

    if( (temp_int < 360) && (Alert_Flag == 1) )
    {
    	Alert_Flag = 0;
    	snprintf(msg.topic, sizeof(msg.topic), "%s1", TOPIC_SUB_CMD_PREFIX); // "bridge/cmd/1"
    	snprintf(msg.payload, sizeof(msg.payload), "CONT OFF");
    	MqttMsg_t *msg_ptr = (MqttMsg_t*)pvPortMalloc(sizeof(MqttMsg_t));
    	if (msg_ptr != NULL) {
    	  memcpy(msg_ptr, &msg, sizeof(MqttMsg_t));
    	  osStatus_t st = osMessageQueuePut(qMqttTxHandle, &msg_ptr, 0, pdMS_TO_TICKS(100));
    	  if (st != osOK) vPortFree(msg_ptr);
    	}
    }

    snprintf(msg.topic, sizeof(msg.topic), "%s1", TOPIC_PUB_ENV_PREFIX); // "bridge/cmd/1"
    snprintf(msg.payload, sizeof(msg.payload),
                     "{\"id\":1,\"ts\":\"%04d-%02d-%02d %02d:%02d:%02d\",\"msg_id\":%ld,\"origen\":\"%d\",\"temp\":%d,\"hum\":%ld}",
                     2000 + sDate.Year, sDate.Month, sDate.Date,
                     sTime.Hours, sTime.Minutes, sTime.Seconds,
                     id_msg,
                     reason,
                     temp_int,
                     hum);

    MqttMsg_t *msg_ptr = (MqttMsg_t*)pvPortMalloc(sizeof(MqttMsg_t));
    if (msg_ptr != NULL) {
      memcpy(msg_ptr, &msg, sizeof(MqttMsg_t));
      osStatus_t st = osMessageQueuePut(qMqttTxHandle, &msg_ptr, 0, pdMS_TO_TICKS(100));
      if (st != osOK) vPortFree(msg_ptr);
    }
    id_msg++;

  }
  /* USER CODE END task_envReadFunc */
}
#endif

#if NODE_ID == NODE_ID_ACCEL
void Accel_Task_Func(void *argument)
{
  /* USER CODE BEGIN Accel_Task_Func */
  log_printf("[ACC] Task start (FIFO)\r\n");

  if (BSP_ACCELERO_Init() != ACCELERO_OK)
  {
    dbg_printf("[ACC] Init FAIL\r\n");
    for(;;) osDelay(1000);
  }

  program_alarm_RTC();

  uint8_t continuous = 0;

  /* Infinite loop */
  for (;;)
  {
    uint32_t flags = osThreadFlagsWait( NOTE_BUTTON_IRQ | NOTE_RTC_WAKEUP | NOTE_CMD_RX,
                                       osFlagsWaitAny,
                                       osWaitForever);

    if (flags & NOTE_CMD_RX)
    {
    	SystemCommandMsg_t cmd;
    	while (osMessageQueueGet(qCmdRxHandle, &cmd, NULL, 0) == osOK)
    	{
    	  if (cmd.type == CMD_SET_RTC) {
    		  ApplyRTC(&cmd.u.rtc);
    		  program_alarm_RTC();
    		}
    	  if (cmd.type == CMD_START_CONTINUOUS) continuous = 1;
    	  if (cmd.type == CMD_STOP_CONTINUOUS)  continuous = 0;
    	  if (cmd.type == CMD_FORCE_READ) osThreadFlagsSet(Accel_TaskHandle, NOTE_RTC_WAKEUP);

    	  if (cmd.type == CMD_SET_WIFI) {
    	     strncpy(g_wifi_ssid, cmd.u.wifi.ssid, WIFI_SSID_MAX);
    	     strncpy(g_wifi_pass, cmd.u.wifi.pass, WIFI_PASS_MAX);
    	     WIFI_STATE = 0;
    	     WIFI_IS_CONNECTED = 0;
    	     NET_MQTT_OK = 0;
    	  }
    	}

    }

    if (flags &  NOTE_BUTTON_IRQ) {
        flags |= NOTE_RTC_WAKEUP;
    }

    if (!(flags & NOTE_RTC_WAKEUP))
        continue;

    if (flags & NOTE_RTC_WAKEUP) {
        program_alarm_RTC();
    }

    const uint16_t target       = continuous ? ACC_CONT_SAMPLES : ACC_BLOCK_SAMPLES; // 1024 o 64
    const uint16_t total_chunks = (uint16_t)(target / ACC_BLOCK_SAMPLES);            // 16 o 1
    const uint16_t watermark_samples = ACC_BLOCK_SAMPLES;                            // 64
    const uint16_t watermark_words   = watermark_samples * 3;                        // 192 words

    log_printf("[ACC] Capture start FIFO mode=%s target=%u\r\n",
           continuous ? "CONT" : "NORMAL", target);

    // Reconfig FIFO
    LSM6DSL_FifoReset();
    LSM6DSL_FifoConfig(watermark_samples);

    (void)osThreadFlagsClear(NOTE_ACCEL_FIFO);

    const uint32_t t0_ms = now_ms();

    int16_t z_block_mg[ACC_BLOCK_SAMPLES];
    uint16_t block_fill = 0;
    uint16_t collected  = 0;
    uint16_t seq        = 0;

    while (collected < target)
    {
      // Espera evento FIFO… pero con fallback si se perdió el flanco
      uint32_t r = osThreadFlagsWait(NOTE_ACCEL_FIFO, osFlagsWaitAny, 1500);

      // Lee nivel actual de FIFO
      uint16_t level_words = LSM6DSL_FifoGetLevelWords();

      if (r == (uint32_t)osErrorTimeout)
      {
        if (level_words < watermark_words)
        {
          log_printf("[ACC] TIMEOUT FIFO event, level_words=%u (<%u)\r\n",
                 (unsigned)level_words, (unsigned)watermark_words);
          continue;
        }
        // si >= watermark: procesamos aunque no entró ISR
        log_printf("[ACC] Missed INT? level_words=%u (>= watermark)\r\n",
               (unsigned)level_words);
      }

      while (level_words >= 3 && collected < target)
      {
        int16_t x_raw, y_raw, z_raw;
        LSM6DSL_FifoReadXYZRaw(&x_raw, &y_raw, &z_raw);
        level_words -= 3;

        int16_t z_mg = (int16_t)((float)z_raw * LSM6DSL_ACC_SENSITIVITY_2G);

        z_block_mg[block_fill++] = z_mg;
        collected++;

        if (block_fill == ACC_BLOCK_SAMPLES)
        {
          char payload[MSG_PAYLOAD_SIZE];

          build_payload_block(payload, sizeof(payload),
                              t0_ms, ACC_FS_HZ,
                              seq, total_chunks,
                              z_block_mg, ACC_BLOCK_SAMPLES);

          log_printf("[ACC][JSON] %s\r\n", payload);

          char topic[MSG_TOPIC_SIZE];
          snprintf(topic, sizeof(topic), "%s%d", TOPIC_PUB_ACCEL_PREFIX, NODE_ID);
          send_mqtt_msg(topic, payload);

          seq++;
          block_fill = 0;
        }
      }
    }

    LSM6DSL_FifoReset();
    log_printf("[ACC] Done FIFO. collected=%u chunks=%u\r\n",
           (unsigned)collected, (unsigned)seq);
  }
  /* USER CODE END Accel_Task_Func */
}
#endif

void UartCfgTask_Func(void *argument)
{
  for (;;)
  {
    osThreadFlagsWait(NOTE_UART_LINE, osFlagsWaitAny, osWaitForever);
    if (!uart_line_has_ready) continue;
    uart_line_has_ready = 0;

    SystemCommandMsg_t cmd;
    if (!Cmd_ParseLine(uart_line_ready, CMD_SRC_UART, &cmd)) {
      log_printf("[UART] cmd desconocido o formato invalido: %s\r\n", uart_line_ready);
      continue;
    }

    DispatchCommand(&cmd);
  }
}

void HAL_TIM_PeriodElapsedCallback(TIM_HandleTypeDef *htim)
{
  if (htim->Instance == TIM6)
  {
    HAL_IncTick();
  }
}

void Error_Handler(void)
{
  __disable_irq();
  while (1)
  {
  }
}
#ifdef USE_FULL_ASSERT
/**
  * @brief  Reports the name of the source file and the source line number
  *         where the assert_param error has occurred.
  * @param  file: pointer to the source file name
  * @param  line: assert_param error line source number
  * @retval None
  */
void assert_failed(uint8_t *file, uint32_t line)
{
  /* USER CODE BEGIN 6 */
  /* User can add his own implementation to report the file name and line number,
     ex: dbg_printf("Wrong parameters value: file %s on line %d\r\n", file, line) */
  /* USER CODE END 6 */
}
#endif /* USE_FULL_ASSERT */

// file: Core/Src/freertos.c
/* USER CODE BEGIN Header */
/**
  ******************************************************************************
  * File Name          : freertos.c
  * Description        : Code for freertos applications
  ******************************************************************************
  * @attention
  *
  * Copyright (c) 2026 STMicroelectronics.
  * All rights reserved.
  *
  * This software is licensed under terms that can be found in the LICENSE file
  * in the root directory of this software component.
  * If no LICENSE file comes with this software, it is provided AS-IS.
  *
  ******************************************************************************
  */
/* USER CODE END Header */

#include "FreeRTOS.h"
#include "task.h"
#include "main.h"
#include "cmsis_os.h"

/* Definitions for WifiTask */
osThreadId_t WifiTaskHandle;
const osThreadAttr_t WifiTask_attributes = {
  .name = "WifiTask",
  .stack_size = 512 * 4,
  .priority = (osPriority_t) osPriorityNormal,
};
/* Definitions for MQTT_Task */
osThreadId_t MQTT_TaskHandle;
const osThreadAttr_t MQTT_Task_attributes = {
  .name = "MQTT_Task",
  .stack_size = 512 * 4,
  .priority = (osPriority_t) osPriorityLow,
};
/* Definitions for task_envRead */
osThreadId_t task_envReadHandle;
const osThreadAttr_t task_envRead_attributes = {
  .name = "task_envRead",
  .stack_size = 512 * 4,
  .priority = (osPriority_t) osPriorityNormal,
};
/* Definitions for Accel_Task */
osThreadId_t Accel_TaskHandle;
const osThreadAttr_t Accel_Task_attributes = {
  .name = "Accel_Task",
  .stack_size = 512 * 4,
  .priority = (osPriority_t) osPriorityNormal,
};
/* Definitions for Uart_Task */
osThreadId_t Uart_TaskHandle;
const osThreadAttr_t Uart_Task_attributes = {
  .name = "Uart_Task",
  .stack_size = 512 * 4,
  .priority = (osPriority_t) osPriorityNormal,
};
/* Definitions for qMqttTx */
osMessageQueueId_t qMqttTxHandle;
const osMessageQueueAttr_t qMqttTx_attributes = {
  .name = "qMqttTx"
};
/* Definitions for qCmdRx */
osMessageQueueId_t qCmdRxHandle;
const osMessageQueueAttr_t qCmdRx_attributes = {
  .name = "qCmdRx"
};

void StartWifiTask(void *argument);
void MQTT_TaskFun(void *argument);
void task_envReadFunc(void *argument);
void Accel_Task_fun(void *argument);
void Uart_Task_Fun(void *argument);

void MX_FREERTOS_Init(void); /* (MISRA C 2004 rule 8.1) */

void MX_FREERTOS_Init(void) {

  /* Create the queue(s) */
  /* creation of qMqttTx */
  qMqttTxHandle = osMessageQueueNew (16, 160, &qMqttTx_attributes);

  /* creation of qCmdRx */
  qCmdRxHandle = osMessageQueueNew (5, sizeof(uint8_t), &qCmdRx_attributes);

  /* Create the thread(s) */
  /* creation of WifiTask */
  WifiTaskHandle = osThreadNew(StartWifiTask, NULL, &WifiTask_attributes);

  /* creation of MQTT_Task */
  MQTT_TaskHandle = osThreadNew(MQTT_TaskFun, NULL, &MQTT_Task_attributes);

  /* creation of task_envRead */
  task_envReadHandle = osThreadNew(task_envReadFunc, NULL, &task_envRead_attributes);

  /* creation of Accel_Task */
  Accel_TaskHandle = osThreadNew(Accel_Task_fun, NULL, &Accel_Task_attributes);

  /* creation of Uart_Task */
  Uart_TaskHandle = osThreadNew(Uart_Task_Fun, NULL, &Uart_Task_attributes);

}

void StartWifiTask(void *argument)
{
  for(;;)
  {
    osDelay(1);
  }
}

void MQTT_TaskFun(void *argument)
{
  for(;;)
  {
    osDelay(1);
  }
}

void task_envReadFunc(void *argument)
{
  for(;;)
  {
    osDelay(1);
  }
}

void Accel_Task_fun(void *argument)
{
  for(;;)
  {
    osDelay(1);
  }
}

void Uart_Task_Fun(void *argument)
{
  for(;;)
  {
    osDelay(1);
  }
}
